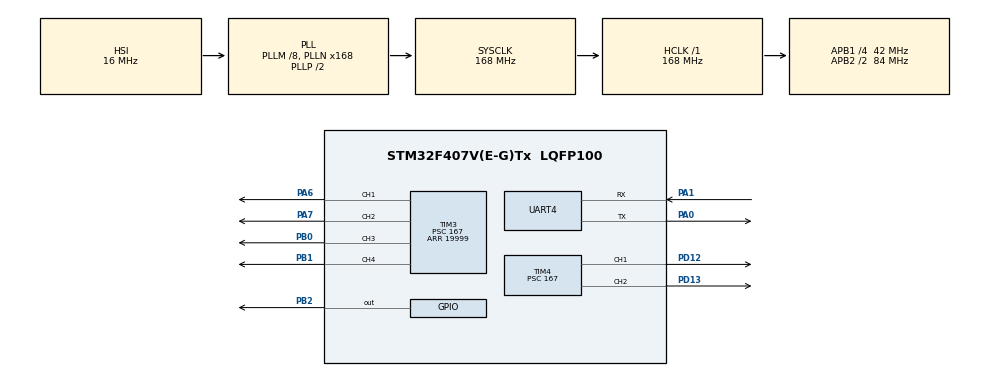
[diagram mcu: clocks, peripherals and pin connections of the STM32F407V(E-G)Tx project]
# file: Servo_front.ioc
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Dma.Request0=UART4_RX
Dma.UART4_RX.0.Direction=DMA_PERIPH_TO_MEMORY
Dma.UART4_RX.0.FIFOMode=DMA_FIFOMODE_DISABLE
Dma.UART4_RX.0.Instance=DMA1_Stream2
Dma.UART4_RX.0.MemDataAlignment=DMA_MDATAALIGN_BYTE
Dma.UART4_RX.0.MemInc=DMA_MINC_ENABLE
Dma.UART4_RX.0.Mode=DMA_CIRCULAR
Dma.UART4_RX.0.PeriphDataAlignment=DMA_PDATAALIGN_BYTE
Dma.UART4_RX.0.PeriphInc=DMA_PINC_DISABLE
Dma.UART4_RX.0.Priority=DMA_PRIORITY_VERY_HIGH
Mcu.Family=STM32F4
Mcu.Name=STM32F407V(E-G)Tx
Mcu.Package=LQFP100
NVIC.DMA1_Stream2_IRQn=true\:0\:0\:false\:false\:true\:false\:true\:true
NVIC.PriorityGroup=NVIC_PRIORITYGROUP_4
NVIC.UART4_IRQn=true\:0\:0\:false\:false\:true\:true\:true\:true
PA0-WKUP.Mode=Asynchronous
PA0-WKUP.Signal=UART4_TX
PA1.Mode=Asynchronous
PA1.Signal=UART4_RX
PA13.Mode=Serial_Wire
PA13.Signal=SYS_JTMS-SWDIO
PA14.Mode=Serial_Wire
PA14.Signal=SYS_JTCK-SWCLK
PA6.Signal=S_TIM3_CH1
PA7.Signal=S_TIM3_CH2
PB0.Signal=S_TIM3_CH3
PB1.Signal=S_TIM3_CH4
PB2.GPIO_ModeDefaultOutputPP=GPIO_MODE_OUTPUT_PP
PB2.GPIO_PuPd=GPIO_PULLDOWN
PB2.Signal=GPIO_Output
PD12.Signal=S_TIM4_CH1
PD13.Signal=S_TIM4_CH2
PH0-OSC_IN.Mode=HSE-External-Oscillator
PH0-OSC_IN.Signal=RCC_OSC_IN
PH1-OSC_OUT.Mode=HSE-External-Oscillator
PH1-OSC_OUT.Signal=RCC_OSC_OUT
ProjectManager.HeapSize=0x200
ProjectManager.StackSize=0x400
ProjectManager.TargetToolchain=MDK-ARM V5.32
RCC.48MHZClocksFreq_Value=84000000
RCC.AHBFreq_Value=168000000
RCC.APB1CLKDivider=RCC_HCLK_DIV4
RCC.APB1Freq_Value=42000000
RCC.APB1TimFreq_Value=84000000
RCC.APB2CLKDivider=RCC_HCLK_DIV2
RCC.APB2Freq_Value=84000000
RCC.APB2TimFreq_Value=168000000
RCC.CortexFreq_Value=168000000
RCC.HCLKFreq_Value=168000000
RCC.HSE_VALUE=25000000
RCC.HSI_VALUE=16000000
RCC.LSE_VALUE=32768
RCC.PLLM=8
RCC.PLLN=168
RCC.SYSCLKFreq_VALUE=168000000
RCC.SYSCLKSource=RCC_SYSCLKSOURCE_PLLCLK
RCC.VCOOutputFreq_Value=336000000
SH.S_TIM3_CH1.0=TIM3_CH1,PWM Generation1 CH1
SH.S_TIM3_CH2.0=TIM3_CH2,PWM Generation2 CH2
SH.S_TIM3_CH3.0=TIM3_CH3,PWM Generation3 CH3
SH.S_TIM3_CH4.0=TIM3_CH4,PWM Generation4 CH4
SH.S_TIM4_CH1.0=TIM4_CH1,PWM Generation1 CH1
SH.S_TIM4_CH2.0=TIM4_CH2,PWM Generation2 CH2
TIM3.Channel-PWM\ Generation1\ CH1=TIM_CHANNEL_1
TIM3.Channel-PWM\ Generation2\ CH2=TIM_CHANNEL_2
TIM3.Channel-PWM\ Generation3\ CH3=TIM_CHANNEL_3
TIM3.Channel-PWM\ Generation4\ CH4=TIM_CHANNEL_4
TIM3.Period=19999
TIM3.Prescaler=167
TIM4.Channel-PWM\ Generation1\ CH1=TIM_CHANNEL_1
TIM4.Channel-PWM\ Generation2\ CH2=TIM_CHANNEL_2
TIM4.Period=19999
TIM4.Prescaler=167
UART4.VirtualMode=Asynchronous
board=custom

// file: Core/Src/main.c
/* USER CODE BEGIN Header */
/**
  ******************************************************************************
  * @file           : main.c
  * @brief          : Main program body
  ******************************************************************************
  * @attention
  *
  * Copyright (c) 2025 STMicroelectronics.
  * All rights reserved.
  *
  * This software is licensed under terms that can be found in the LICENSE file
  * in the root directory of this software component.
  * If no LICENSE file comes with this software, it is provided AS-IS.
  *
  ******************************************************************************
  */
/* USER CODE END Header */
#include "main.h"
#include "dma.h"
#include "tim.h"
#include "usart.h"
#include "gpio.h"

/* USER CODE BEGIN Includes */
#include "Servo_front.h"
#include "Serial.h"

/* USER CODE END Includes */

/* USER CODE BEGIN PM */
//void Serial_Init(UART_HandleTypeDef *huart, uint8_t *DstAddress, uint8_t *SecondMemAddress, uint32_t DataLength);

/* USER CODE END PM */

/* USER CODE BEGIN PV */
volatile uint8_t control_rx_buf[2][RX_Control_User_add] = {0};

/* USER CODE END PV */

void SystemClock_Config(void);

int main(void)
{

  /* MCU Configuration--------------------------------------------------------*/

  /* Reset of all peripherals, Initializes the Flash interface and the Systick. */
  HAL_Init();

  /* Configure the system clock */
  SystemClock_Config();

  /* Initialize all configured peripherals */
  MX_GPIO_Init();
  MX_DMA_Init();
  MX_TIM3_Init();
  MX_TIM4_Init();
  MX_UART4_Init();
  /* USER CODE BEGIN 2 */
  Servo_Front_Init();
  USART_DMAEx_MultiBuffer_Init(&huart4, (uint32_t*)control_rx_buf[0], (uint32_t*)control_rx_buf[1], RX_Control_User_add);
  HAL_Delay(1000);
  HAL_GPIO_WritePin(GPIOB, GPIO_PIN_2, GPIO_PIN_SET);

  /* USER CODE END 2 */

  /* Infinite loop */
  while (1)
  {

  }
}

void SystemClock_Config(void)
{
  RCC_OscInitTypeDef RCC_OscInitStruct = {0};
  RCC_ClkInitTypeDef RCC_ClkInitStruct = {0};

  /** Configure the main internal regulator output voltage
  */
  __HAL_RCC_PWR_CLK_ENABLE();
  __HAL_PWR_VOLTAGESCALING_CONFIG(PWR_REGULATOR_VOLTAGE_SCALE1);

  /** Initializes the RCC Oscillators according to the specified parameters
  * in the RCC_OscInitTypeDef structure.
  */
  RCC_OscInitStruct.OscillatorType = RCC_OSCILLATORTYPE_HSI;
  RCC_OscInitStruct.HSIState = RCC_HSI_ON;
  RCC_OscInitStruct.HSICalibrationValue = RCC_HSICALIBRATION_DEFAULT;
  RCC_OscInitStruct.PLL.PLLState = RCC_PLL_ON;
  RCC_OscInitStruct.PLL.PLLSource = RCC_PLLSOURCE_HSI;
  RCC_OscInitStruct.PLL.PLLM = 8;
  RCC_OscInitStruct.PLL.PLLN = 168;
  RCC_OscInitStruct.PLL.PLLP = RCC_PLLP_DIV2;
  RCC_OscInitStruct.PLL.PLLQ = 4;
  if (HAL_RCC_OscConfig(&RCC_OscInitStruct) != HAL_OK)
  {
    Error_Handler();
  }

  /** Initializes the CPU, AHB and APB buses clocks
  */
  RCC_ClkInitStruct.ClockType = RCC_CLOCKTYPE_HCLK|RCC_CLOCKTYPE_SYSCLK
                              |RCC_CLOCKTYPE_PCLK1|RCC_CLOCKTYPE_PCLK2;
  RCC_ClkInitStruct.SYSCLKSource = RCC_SYSCLKSOURCE_PLLCLK;
  RCC_ClkInitStruct.AHBCLKDivider = RCC_SYSCLK_DIV1;
  RCC_ClkInitStruct.APB1CLKDivider = RCC_HCLK_DIV4;
  RCC_ClkInitStruct.APB2CLKDivider = RCC_HCLK_DIV2;

  if (HAL_RCC_ClockConfig(&RCC_ClkInitStruct, FLASH_LATENCY_5) != HAL_OK)
  {
    Error_Handler();
  }
}

/* USER CODE BEGIN 4 */

//void Serial_Init(UART_HandleTypeDef *huart, uint8_t *DstAddress, uint8_t *SecondMemAddress, uint32_t DataLength)
//{
//    huart->ReceptionType = HAL_UART_RECEPTION_TOIDLE;

//    huart->RxEventType = HAL_UART_RXEVENT_IDLE;

//    huart->RxXferSize = DataLength;

//    SET_BIT(huart->Instance->CR3, USART_CR3_DMAR);

//    __HAL_UART_ENABLE_IT(huart, UART_IT_IDLE);
//
//    HAL_DMAEx_MultiBufferStart(huart->hdmarx, (uint32_t) &huart->Instance->DR, (uint32_t) DstAddress, (uint32_t) SecondMemAddress, DataLength);
//}

/* USER CODE END 4 */

void Error_Handler(void)
{
  __disable_irq();
  while (1)
  {
  }
}
